CM_ "IMPORT _honda_common.dbc";
CM_ "IMPORT _nidec_common.dbc";
CM_ "IMPORT _nidec_scm_group_a.dbc";
CM_ "IMPORT _steering_sensors_b.dbc";
CM_ "IMPORT _steering_control_a.dbc";
CM_ "IMPORT _gearbox_common.dbc";

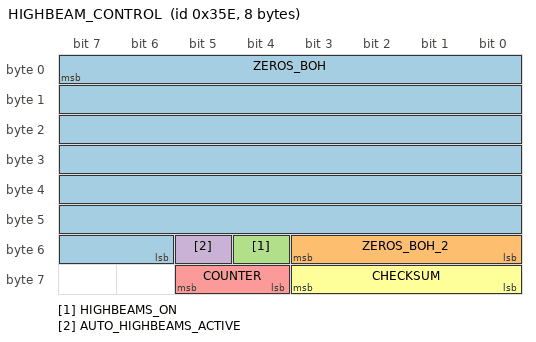
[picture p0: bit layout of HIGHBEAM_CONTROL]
BO_ 862 HIGHBEAM_CONTROL: 8 ADAS
 SG_ ZEROS_BOH : 7|50@0+ (1,0) [0|127] "" BDY
 SG_ ZEROS_BOH_2 : 48|4@1+ (1,0) [0|15] "" XXX
 SG_ HIGHBEAMS_ON : 52|1@0+ (1,0) [0|1] "" XXX
 SG_ AUTO_HIGHBEAMS_ACTIVE : 53|1@0+ (1,0) [0|1] "" XXX
 SG_ COUNTER : 61|2@0+ (1,0) [0|3] "" XXX
 SG_ CHECKSUM : 59|4@0+ (1,0) [0|15] "" XXX
